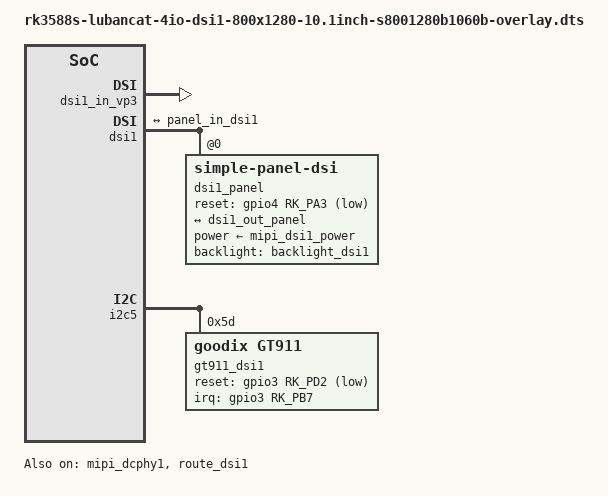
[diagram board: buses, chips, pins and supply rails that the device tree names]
/dts-v1/;
/plugin/;

#include <dt-bindings/gpio/gpio.h>
#include <dt-bindings/pinctrl/rockchip.h>
#include <dt-bindings/display/drm_mipi_dsi.h>
#include <dt-bindings/interrupt-controller/irq.h>

/ {
	fragment@0 {
		target = <&mipi_dcphy1>;

		__overlay__ {
			status = "okay";
		};
	};

	fragment@1 {
		target = <&route_dsi1>;

		__overlay__ {
			status = "okay";
			connect = <&vp3_out_dsi1>;
		};
	};

	fragment@2 {
		target = <&dsi1_in_vp3>;

		__overlay__ {
			status = "okay";
		};
	};

	fragment@3 {
		target = <&dsi1>;

		__overlay__ {
			status = "okay";
			#address-cells = <1>;
			#size-cells = <0>;

			dsi1_panel: panel@0 {
				status = "okay";
				compatible = "simple-panel-dsi";
				reg = <0>;
				backlight = <&backlight_dsi1>;
				power-supply = <&mipi_dsi1_power>;
				reset-gpios = <&gpio4 RK_PA3 GPIO_ACTIVE_LOW>;

				enable-delay-ms = <35>;
				prepare-delay-ms = <6>;
				reset-delay-ms = <0>;
				init-delay-ms = <20>;
				unprepare-delay-ms = <0>;
				disable-delay-ms = <20>;

				size,width = <74>;
				size,height = <133>;

				dsi,flags = <(MIPI_DSI_MODE_VIDEO | MIPI_DSI_MODE_VIDEO_BURST | MIPI_DSI_MODE_LPM | MIPI_DSI_MODE_NO_EOT_PACKET)>;
				dsi,format = <MIPI_DSI_FMT_RGB888>;
				dsi,lanes  = <4>;

				panel-init-sequence = [
					15 00 02 E0 00
					15 00 02 E1 93
					15 00 02 E2 65
					15 00 02 E3 F8
					15 00 02 80 03
					15 00 02 E0 01
					15 00 02 00 00
					15 00 02 01 3B
					15 00 02 0C 74
					15 00 02 17 00
					15 00 02 18 AF
					15 00 02 19 00
					15 00 02 1A 00
					15 00 02 1B AF
					15 00 02 1C 00
					15 00 02 35 26
					15 00 02 37 09
					15 00 02 38 04
					15 00 02 39 00
					15 00 02 3A 01
					15 00 02 3C 78
					15 00 02 3D FF
					15 00 02 3E FF
					15 00 02 3F 7F
					15 00 02 40 06
					15 00 02 41 A0
					15 00 02 42 81
					15 00 02 43 1E
					15 00 02 44 0B
					15 00 02 45 28
					15 00 02 55 02
					15 00 02 57 69
					15 00 02 59 0A
					15 00 02 5A 2A
					15 00 02 5B 17
					15 00 02 5D 7F
					15 00 02 5E 6B
					15 00 02 5F 5C
					15 00 02 60 4F
					15 00 02 61 4D
					15 00 02 62 3F
					15 00 02 63 42
					15 00 02 64 2B
					15 00 02 65 44
					15 00 02 66 43
					15 00 02 67 43
					15 00 02 68 63
					15 00 02 69 52
					15 00 02 6A 5A
					15 00 02 6B 4F
					15 00 02 6C 4E
					15 00 02 6D 20
					15 00 02 6E 0F
					15 00 02 6F 00
					15 00 02 70 7F
					15 00 02 71 6B
					15 00 02 72 5C
					15 00 02 73 4F
					15 00 02 74 4D
					15 00 02 75 3F
					15 00 02 76 42
					15 00 02 77 2B
					15 00 02 78 44
					15 00 02 79 43
					15 00 02 7A 43
					15 00 02 7B 63
					15 00 02 7C 52
					15 00 02 7D 5A
					15 00 02 7E 4F
					15 00 02 7F 4E
					15 00 02 80 20
					15 00 02 81 0F
					15 00 02 82 00
					15 00 02 E0 02
					15 00 02 00 42
					15 00 02 01 42
					15 00 02 02 40
					15 00 02 03 40
					15 00 02 04 5E
					15 00 02 05 5E
					15 00 02 06 5F
					15 00 02 07 5F
					15 00 02 08 5F
					15 00 02 09 57
					15 00 02 0A 57
					15 00 02 0B 77
					15 00 02 0C 77
					15 00 02 0D 47
					15 00 02 0E 47
					15 00 02 0F 45
					15 00 02 10 45
					15 00 02 11 4B
					15 00 02 12 4B
					15 00 02 13 49
					15 00 02 14 49
					15 00 02 15 5F
					15 00 02 16 41
					15 00 02 17 41
					15 00 02 18 40
					15 00 02 19 40
					15 00 02 1A 5E
					15 00 02 1B 5E
					15 00 02 1C 5F
					15 00 02 1D 5F
					15 00 02 1E 5F
					15 00 02 1F 57
					15 00 02 20 57
					15 00 02 21 77
					15 00 02 22 77
					15 00 02 23 46
					15 00 02 24 46
					15 00 02 25 44
					15 00 02 26 44
					15 00 02 27 4A
					15 00 02 28 4A
					15 00 02 29 48
					15 00 02 2A 48
					15 00 02 2B 5F
					15 00 02 2C 01
					15 00 02 2D 01
					15 00 02 2E 00
					15 00 02 2F 00
					15 00 02 30 1F
					15 00 02 31 1F
					15 00 02 32 1E
					15 00 02 33 1E
					15 00 02 34 1F
					15 00 02 35 17
					15 00 02 36 17
					15 00 02 37 37
					15 00 02 38 37
					15 00 02 39 08
					15 00 02 3A 08
					15 00 02 3B 0A
					15 00 02 3C 0A
					15 00 02 3D 04
					15 00 02 3E 04
					15 00 02 3F 06
					15 00 02 40 06
					15 00 02 41 1F
					15 00 02 42 02
					15 00 02 43 02
					15 00 02 44 00
					15 00 02 45 00
					15 00 02 46 1F
					15 00 02 47 1F
					15 00 02 48 1E
					15 00 02 49 1E
					15 00 02 4A 1F
					15 00 02 4B 17
					15 00 02 4C 17
					15 00 02 4D 37
					15 00 02 4E 37
					15 00 02 4F 09
					15 00 02 50 09
					15 00 02 51 0B
					15 00 02 52 0B
					15 00 02 53 05
					15 00 02 54 05
					15 00 02 55 07
					15 00 02 56 07
					15 00 02 57 1F
					15 00 02 58 40
					15 00 02 5B 30
					15 00 02 5C 00
					15 00 02 5D 34
					15 00 02 5E 05
					15 00 02 5F 02
					15 00 02 63 00
					15 00 02 64 6A
					15 00 02 67 73
					15 00 02 68 05
					15 00 02 69 08
					15 00 02 6A 6A
					15 00 02 6B 08
					15 00 02 6C 00
					15 00 02 6D 00
					15 00 02 6E 00
					15 00 02 6F 88
					15 00 02 75 FF
					15 00 02 77 DD
					15 00 02 78 2A
					15 00 02 79 15
					15 00 02 7A 17
					15 00 02 7D 14
					15 00 02 7E 82
					15 00 02 E0 04
					15 00 02 00 0E
					15 00 02 02 B3
					15 00 02 09 61
					15 00 02 0E 48
					15 00 02 E0 00
					15 00 02 E6 02
					15 00 02 E7 0C
					15 78 02 11 00
					15 00 02 E0 00
					15 05 02 29 00
				];

				panel-exit-sequence = [
					05 78 01 28
					05 00 01 10
				];

				disp1_timings0: display-timings {
					native-mode = <&dsi1_timing0>;
					dsi1_timing0: timing0 {
						clock-frequency = <69801600>;
						hactive = <800>;
						vactive = <1280>;
						hsync-len = <20>;
						hback-porch = <20>;
						hfront-porch = <40>;
						vsync-len = <4>;
						vback-porch = <8>;
						vfront-porch = <30>;
						hsync-active = <0>;
						vsync-active = <0>;
						de-active = <0>;
						pixelclk-active = <0>;
					};
				};

				ports {
					#address-cells = <1>;
					#size-cells = <0>;
					port@0 {
						reg = <0>;
						panel_in_dsi1: endpoint {
							remote-endpoint = <&dsi1_out_panel>;
						};
					};
				};
			};

			ports {
				#address-cells = <1>;
				#size-cells = <0>;

				port@1 {
					reg = <1>;
					dsi1_out_panel: endpoint {
						remote-endpoint = <&panel_in_dsi1>;
					};
				};
			};
		};
	};

	fragment@4 {
		target = <&i2c5>;

		__overlay__ {
			status = "okay";
			#address-cells = <1>;
			#size-cells = <0>;
			pinctrl-names = "default";
			pinctrl-0 = <&i2c5m3_xfer>;

			gt911_dsi1: gt911@5d {
				status = "okay";
				compatible = "goodix,gt911";
				reg = <0x5d>;
				interrupt-parent = <&gpio3>;
				interrupts = <RK_PB7 IRQ_TYPE_LEVEL_LOW>;
				reset-gpios = <&gpio3 RK_PD2 GPIO_ACTIVE_LOW>;
				irq-gpios = <&gpio3 RK_PB7 GPIO_ACTIVE_HIGH>;
				touchscreen-inverted-x = <1>;
				touchscreen-swapped-x-y = <1>;
			};
		};
	};
};
